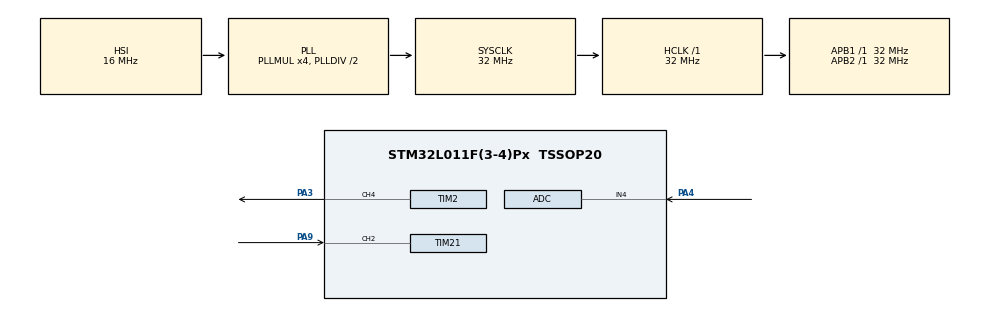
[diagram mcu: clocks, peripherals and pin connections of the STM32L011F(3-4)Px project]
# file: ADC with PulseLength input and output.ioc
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ADC.DiscontinuousConvMode=ENABLE
Mcu.Family=STM32L0
Mcu.Name=STM32L011F(3-4)Px
Mcu.Package=TSSOP20
NVIC.ADC1_COMP_IRQn=true\:0\:0\:false\:false\:true\:true\:true\:true
NVIC.TIM21_IRQn=true\:0\:0\:false\:false\:true\:true\:true\:true
NVIC.TIM2_IRQn=true\:0\:0\:false\:false\:true\:true\:true\:true
PA13.Mode=Serial_Wire
PA13.Signal=SYS_SWDIO
PA14.Mode=Serial_Wire
PA14.Signal=SYS_SWCLK
PA3.Signal=S_TIM2_CH4
PA4.Mode=IN4
PA4.Signal=ADC_IN4
PA9.Signal=S_TIM21_CH2
ProjectManager.HeapSize=0x200
ProjectManager.StackSize=0x400
ProjectManager.TargetToolchain=STM32CubeIDE
RCC.AHBFreq_Value=32000000
RCC.APB1Freq_Value=32000000
RCC.APB1TimFreq_Value=32000000
RCC.APB2Freq_Value=32000000
RCC.APB2TimFreq_Value=32000000
RCC.HCLKFreq_Value=32000000
RCC.HSE_VALUE=8000000
RCC.HSI16_VALUE=16000000
RCC.HSI_VALUE=16000000
RCC.LSE_VALUE=32768
RCC.MSI_VALUE=2097000
RCC.PLLMUL=RCC_PLLMUL_4
RCC.SYSCLKFreq_VALUE=32000000
RCC.SYSCLKSource=RCC_SYSCLKSOURCE_PLLCLK
RCC.VCOOutputFreq_Value=64000000
SH.S_TIM21_CH2.0=TIM21_CH2,PWM_Input_2
SH.S_TIM2_CH4.0=TIM2_CH4,PWM Generation4 CH4
TIM2.Channel-PWM\ Generation4\ CH4=TIM_CHANNEL_4
TIM2.Period=800
TIM2.Prescaler=10-1
TIM21.AutoReloadPreload=TIM_AUTORELOAD_PRELOAD_ENABLE
TIM21.ICPolarity_1=TIM_INPUTCHANNELPOLARITY_FALLING
TIM21.Period=50000
TIM21.Prescaler=16-1
VP_TIM21_VS_ClockSourceINT.Mode=Internal
VP_TIM2_VS_ClockSourceINT.Mode=Internal
board=custom

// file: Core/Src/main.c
/* USER CODE BEGIN Header */
/**
  ******************************************************************************
  * @file           : main.c
  * @brief          : Main program body
  ******************************************************************************
  * @attention
  *
  * Copyright (c) 2023 STMicroelectronics.
  * All rights reserved.
  *
  * This software is licensed under terms that can be found in the LICENSE file
  * in the root directory of this software component.
  * If no LICENSE file comes with this software, it is provided AS-IS.
  *
  ******************************************************************************
  */
/* USER CODE END Header */
#include "main.h"

ADC_HandleTypeDef hadc;

TIM_HandleTypeDef htim2;
TIM_HandleTypeDef htim21;

void SystemClock_Config(void);
static void MX_GPIO_Init(void);
static void MX_ADC_Init(void);
static void MX_TIM2_Init(void);
static void MX_TIM21_Init(void);

/* USER CODE BEGIN 0 */
	//##############################ADC INPUT SENSOR - PID CONTROL############################
	float Thrust_measured = 0;//Newtons
	float Thrust_desired = 0;//Newtons
	//##############################PWM OUTPUT##############################
	uint32_t Frequency_output = 4000; //in Hertz. As we want a max pulse of 250us(Duty_output=100%)
	float Duty_output = 0; //From 0 to 1
	uint32_t Pulse_length_output = 150;//in us (microseconds)
	//############################## PWM INPUT##############################
	float Duty_input = 0; //Duty cycle coefficient: 0->0%, 1->100%
	uint32_t Pulse_length_input = 0;//in us (microseconds)
	uint32_t PWM_input_period = 0; //Period of the PWM function (counts timer clicks)
	uint32_t PWM_input_pulseON = 0; //Pulse width, of the positive part, on.
	uint32_t Frequency_input = 0;//Frequency of the PWM hole function (Hz)
	//#######################################################################
/* USER CODE END 0 */

int main(void)
{

  /* MCU Configuration--------------------------------------------------------*/

  /* Reset of all peripherals, Initializes the Flash interface and the Systick. */
  HAL_Init();

  /* Configure the system clock */
  SystemClock_Config();

  /* Initialize all configured peripherals */
  MX_GPIO_Init();
  MX_ADC_Init();
  MX_TIM2_Init();
  MX_TIM21_Init();
  /* USER CODE BEGIN 2 */
  	  //##############################PWM INPUT##############################
  	  // Main channel (Function Period Measure):
		HAL_TIM_IC_Start_IT(&htim21, TIM_CHANNEL_2);
	  // Indirect channel (Pulse Width Measure):
		HAL_TIM_IC_Start(&htim21, TIM_CHANNEL_1);
	  //##############################PWM OUTPUT##############################
		HAL_TIM_PWM_Start_IT(&htim2, TIM_CHANNEL_4); //Generation initialization.
  /* USER CODE END 2 */

  /* Infinite loop */
  while (1)
  {

  }
}

void SystemClock_Config(void)
{
  RCC_OscInitTypeDef RCC_OscInitStruct = {0};
  RCC_ClkInitTypeDef RCC_ClkInitStruct = {0};

  /** Configure the main internal regulator output voltage
  */
  __HAL_PWR_VOLTAGESCALING_CONFIG(PWR_REGULATOR_VOLTAGE_SCALE1);

  /** Initializes the RCC Oscillators according to the specified parameters
  * in the RCC_OscInitTypeDef structure.
  */
  RCC_OscInitStruct.OscillatorType = RCC_OSCILLATORTYPE_HSI;
  RCC_OscInitStruct.HSIState = RCC_HSI_ON;
  RCC_OscInitStruct.HSICalibrationValue = RCC_HSICALIBRATION_DEFAULT;
  RCC_OscInitStruct.PLL.PLLState = RCC_PLL_ON;
  RCC_OscInitStruct.PLL.PLLSource = RCC_PLLSOURCE_HSI;
  RCC_OscInitStruct.PLL.PLLMUL = RCC_PLLMUL_4;
  RCC_OscInitStruct.PLL.PLLDIV = RCC_PLLDIV_2;
  if (HAL_RCC_OscConfig(&RCC_OscInitStruct) != HAL_OK)
  {
    Error_Handler();
  }

  /** Initializes the CPU, AHB and APB buses clocks
  */
  RCC_ClkInitStruct.ClockType = RCC_CLOCKTYPE_HCLK|RCC_CLOCKTYPE_SYSCLK
                              |RCC_CLOCKTYPE_PCLK1|RCC_CLOCKTYPE_PCLK2;
  RCC_ClkInitStruct.SYSCLKSource = RCC_SYSCLKSOURCE_PLLCLK;
  RCC_ClkInitStruct.AHBCLKDivider = RCC_SYSCLK_DIV1;
  RCC_ClkInitStruct.APB1CLKDivider = RCC_HCLK_DIV1;
  RCC_ClkInitStruct.APB2CLKDivider = RCC_HCLK_DIV1;

  if (HAL_RCC_ClockConfig(&RCC_ClkInitStruct, FLASH_LATENCY_1) != HAL_OK)
  {
    Error_Handler();
  }
}

static void MX_ADC_Init(void)
{

  ADC_ChannelConfTypeDef sConfig = {0};

  /** Configure the global features of the ADC (Clock, Resolution, Data Alignment and number of conversion)
  */
  hadc.Instance = ADC1;
  hadc.Init.OversamplingMode = DISABLE;
  hadc.Init.ClockPrescaler = ADC_CLOCK_SYNC_PCLK_DIV2;
  hadc.Init.Resolution = ADC_RESOLUTION_12B;
  hadc.Init.SamplingTime = ADC_SAMPLETIME_1CYCLE_5;
  hadc.Init.ScanConvMode = ADC_SCAN_DIRECTION_FORWARD;
  hadc.Init.DataAlign = ADC_DATAALIGN_RIGHT;
  hadc.Init.ContinuousConvMode = DISABLE;
  hadc.Init.DiscontinuousConvMode = ENABLE;
  hadc.Init.ExternalTrigConvEdge = ADC_EXTERNALTRIGCONVEDGE_NONE;
  hadc.Init.ExternalTrigConv = ADC_SOFTWARE_START;
  hadc.Init.DMAContinuousRequests = DISABLE;
  hadc.Init.EOCSelection = ADC_EOC_SINGLE_CONV;
  hadc.Init.Overrun = ADC_OVR_DATA_PRESERVED;
  hadc.Init.LowPowerAutoWait = DISABLE;
  hadc.Init.LowPowerFrequencyMode = DISABLE;
  hadc.Init.LowPowerAutoPowerOff = DISABLE;
  if (HAL_ADC_Init(&hadc) != HAL_OK)
  {
    Error_Handler();
  }

  /** Configure for the selected ADC regular channel to be converted.
  */
  sConfig.Channel = ADC_CHANNEL_4;
  sConfig.Rank = ADC_RANK_CHANNEL_NUMBER;
  if (HAL_ADC_ConfigChannel(&hadc, &sConfig) != HAL_OK)
  {
    Error_Handler();
  }

}

static void MX_TIM2_Init(void)
{

  TIM_ClockConfigTypeDef sClockSourceConfig = {0};
  TIM_MasterConfigTypeDef sMasterConfig = {0};
  TIM_OC_InitTypeDef sConfigOC = {0};

  htim2.Instance = TIM2;
  htim2.Init.Prescaler = 10-1;
  htim2.Init.CounterMode = TIM_COUNTERMODE_UP;
  htim2.Init.Period = 800;
  htim2.Init.ClockDivision = TIM_CLOCKDIVISION_DIV1;
  htim2.Init.AutoReloadPreload = TIM_AUTORELOAD_PRELOAD_DISABLE;
  if (HAL_TIM_Base_Init(&htim2) != HAL_OK)
  {
    Error_Handler();
  }
  sClockSourceConfig.ClockSource = TIM_CLOCKSOURCE_INTERNAL;
  if (HAL_TIM_ConfigClockSource(&htim2, &sClockSourceConfig) != HAL_OK)
  {
    Error_Handler();
  }
  if (HAL_TIM_PWM_Init(&htim2) != HAL_OK)
  {
    Error_Handler();
  }
  sMasterConfig.MasterOutputTrigger = TIM_TRGO_RESET;
  sMasterConfig.MasterSlaveMode = TIM_MASTERSLAVEMODE_DISABLE;
  if (HAL_TIMEx_MasterConfigSynchronization(&htim2, &sMasterConfig) != HAL_OK)
  {
    Error_Handler();
  }
  sConfigOC.OCMode = TIM_OCMODE_PWM1;
  sConfigOC.Pulse = 0;
  sConfigOC.OCPolarity = TIM_OCPOLARITY_HIGH;
  sConfigOC.OCFastMode = TIM_OCFAST_DISABLE;
  if (HAL_TIM_PWM_ConfigChannel(&htim2, &sConfigOC, TIM_CHANNEL_4) != HAL_OK)
  {
    Error_Handler();
  }
  HAL_TIM_MspPostInit(&htim2);

}

static void MX_TIM21_Init(void)
{

  TIM_ClockConfigTypeDef sClockSourceConfig = {0};
  TIM_SlaveConfigTypeDef sSlaveConfig = {0};
  TIM_IC_InitTypeDef sConfigIC = {0};
  TIM_MasterConfigTypeDef sMasterConfig = {0};

  htim21.Instance = TIM21;
  htim21.Init.Prescaler = 16-1;
  htim21.Init.CounterMode = TIM_COUNTERMODE_UP;
  htim21.Init.Period = 50000;
  htim21.Init.ClockDivision = TIM_CLOCKDIVISION_DIV1;
  htim21.Init.AutoReloadPreload = TIM_AUTORELOAD_PRELOAD_ENABLE;
  if (HAL_TIM_Base_Init(&htim21) != HAL_OK)
  {
    Error_Handler();
  }
  sClockSourceConfig.ClockSource = TIM_CLOCKSOURCE_INTERNAL;
  if (HAL_TIM_ConfigClockSource(&htim21, &sClockSourceConfig) != HAL_OK)
  {
    Error_Handler();
  }
  if (HAL_TIM_IC_Init(&htim21) != HAL_OK)
  {
    Error_Handler();
  }
  sSlaveConfig.SlaveMode = TIM_SLAVEMODE_RESET;
  sSlaveConfig.InputTrigger = TIM_TS_TI2FP2;
  sSlaveConfig.TriggerPolarity = TIM_INPUTCHANNELPOLARITY_RISING;
  sSlaveConfig.TriggerPrescaler = TIM_ICPSC_DIV1;
  sSlaveConfig.TriggerFilter = 0;
  if (HAL_TIM_SlaveConfigSynchro(&htim21, &sSlaveConfig) != HAL_OK)
  {
    Error_Handler();
  }
  sConfigIC.ICPolarity = TIM_INPUTCHANNELPOLARITY_FALLING;
  sConfigIC.ICSelection = TIM_ICSELECTION_INDIRECTTI;
  sConfigIC.ICPrescaler = TIM_ICPSC_DIV1;
  sConfigIC.ICFilter = 0;
  if (HAL_TIM_IC_ConfigChannel(&htim21, &sConfigIC, TIM_CHANNEL_1) != HAL_OK)
  {
    Error_Handler();
  }
  sConfigIC.ICPolarity = TIM_INPUTCHANNELPOLARITY_RISING;
  sConfigIC.ICSelection = TIM_ICSELECTION_DIRECTTI;
  if (HAL_TIM_IC_ConfigChannel(&htim21, &sConfigIC, TIM_CHANNEL_2) != HAL_OK)
  {
    Error_Handler();
  }
  sMasterConfig.MasterOutputTrigger = TIM_TRGO_RESET;
  sMasterConfig.MasterSlaveMode = TIM_MASTERSLAVEMODE_DISABLE;
  if (HAL_TIMEx_MasterConfigSynchronization(&htim21, &sMasterConfig) != HAL_OK)
  {
    Error_Handler();
  }

}

static void MX_GPIO_Init(void)
{

  /* GPIO Ports Clock Enable */
  __HAL_RCC_GPIOA_CLK_ENABLE();

}

/* USER CODE BEGIN 4 */
float max(float a, float b){if(a>b) return a; else return b;}
float min(float a, float b){if(a>b) return b; else return a;}
float linear_map (float x, float minIN, float maxIN, float minOUT, float maxOUT){
//LINEAR MAPPING from [minIN, maxIN] to [minOUT, maxOUT]
return (x-minIN)*(maxOUT-minOUT)/(maxIN-minIN)+minOUT;}

float integration = 0;
float previous_error = 0;
float PID(float Thrust_desired, float Thrust_measured){
	//To be tunned:
	const float Kff = 0; //Constant for Proportionality directly over desired thrust
	const float Kp = 5.3; //Constant of proportionality over error.
	const float Ki = 0; //Constant of integration
	const float Kd = 0; //Constant of derivation

	float error = 0;
	if(Thrust_measured != 0){
		error = Thrust_desired - Thrust_measured;
	}
	float dt =1;//250/1000000;//250us, As the PID function is evaluated every, due to ADC interrupt function.
	float derivation = (error-previous_error)/dt;
	integration += error*dt;
	//PID
	float Thrust_output = (Kff * Thrust_desired)+(Kp*error)+(Kd*derivation)+(Ki*integration);

	//ANTI-WIND-UP SHIELD. Avoids saturation--------------
	if(Thrust_output > 25){
		integration -= error;
		Thrust_output = 25;//Upper bound
	}
	if(Thrust_output < 0){
		integration -= error;
		Thrust_output = 0;//Lower bound
	}
	//-----------------------------------------------------
	//Security value: not desire input:--------------------
	if(Thrust_desired < 0 || Thrust_desired > 25){
		Thrust_output = 0;
	}
	//-----------------------------------------------------

	previous_error = error;
	return Thrust_output;
}

//################### ADC CONVERSION and PID control #####################
//Frequency of 4kHz as it is initialized in tim2 interrupt HAL_ADC_Start_IT(&hadc);
void HAL_ADC_ConvCpltCallback(ADC_HandleTypeDef* hadc1)
{
	//t_ADC = (t_ADC + 20)%65535;
	//ADC conversion:--------------------------------------------
	Thrust_measured = linear_map(HAL_ADC_GetValue(hadc1) - 577, 1650, 3300, 0, 25);//577 is the offset modification.
	//1650 and 3000 need calibration, as the ADC input value is not estandard, at rest: 1650 aprox.

	//PID control -----------------------------------------------
	float Thrust_PID = PID(Thrust_desired, Thrust_measured);//When tunned, PID function should be replaced by PID_tunned
	//Thrust_PID = Thrust_measured;//test if ADC reading is working.
	//Thrust_PID = Thrust_desired;//test if PWM reading is working.

	Pulse_length_output = linear_map(Thrust_PID, 0, 25, 125, 250);//125 needs calibration (helix weight).

	//Output generation------------------------------------------
	Duty_output=linear_map(Pulse_length_output, 0,250, 0, 1);
	TIM2->CCR4 = (Duty_output*800);//Duty generation configuration. ARR4=800 as Frequency_out is 4kHz
}

//###################PWM INPUT INTERRUPT FUNCTION #####################

void HAL_TIM_IC_CaptureCallback(TIM_HandleTypeDef *htim){

	// Check which version of the timer triggered
	if(htim == &htim21)
	{ //It's called each 10*10000/32000000=3.215ms, as the input PWM frequency is 400Hz
		// If the interrupt is triggered by channel 2
		if (htim->Channel == HAL_TIM_ACTIVE_CHANNEL_2){
			// Read the IC value
			PWM_input_period = HAL_TIM_ReadCapturedValue(htim, TIM_CHANNEL_2);
			//If it ́s not the initial 0 capture (=>no pulse registered)
			if (PWM_input_period != 0){
				PWM_input_pulseON = HAL_TIM_ReadCapturedValue(htim, TIM_CHANNEL_1);
				// Compute the Duty Cycle
				//Duty_input = (float)(PWM_input_pulseON)/(float)PWM_input_period;
				//Compute the frequency of the PWM. 32000000 is the timer frequency
				//Frequency_input = 32000000/(PWM_input_period);//Divide also by prescaler if us

				//Computing the Thrust desired.
				Pulse_length_input = PWM_input_pulseON/2;//PWM_input_pulseON*16*1000000)/32000000)
				Thrust_desired = linear_map(Pulse_length_input, 125, 250, 0, 25);//Depends on the comunication protocol?
				//16 Due to prescaler for tim21, 1000000 to be in micoseconds
			}
		}
	}
}
void HAL_TIM_PWM_PulseFinishedCallback(TIM_HandleTypeDef* htim)
{//Every 250us (microseconds) as the frequency is 400kHz
	if(htim == &htim2)
	{
		//ADC conversion:--------------------------------------------
		HAL_ADC_Start_IT(&hadc);
		//As we are not in continues conversion mode, need to reinitialize
	}
}
/* USER CODE END 4 */

void Error_Handler(void)
{
  __disable_irq();
  while (1)
  {
  }
}
